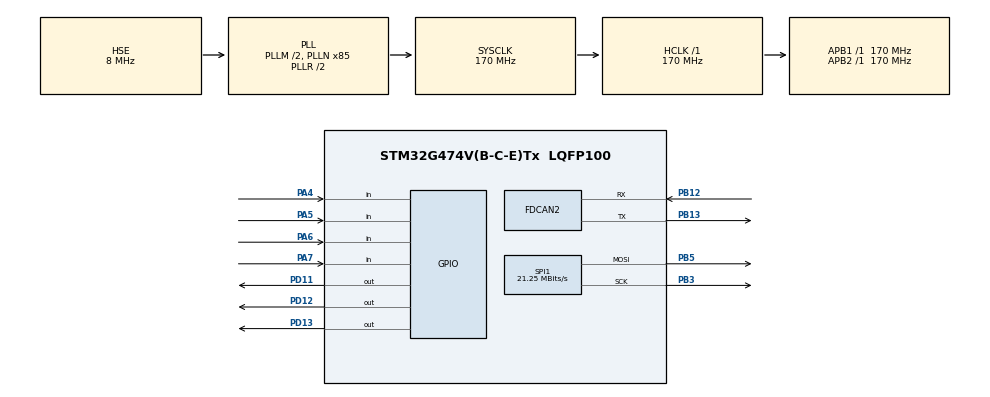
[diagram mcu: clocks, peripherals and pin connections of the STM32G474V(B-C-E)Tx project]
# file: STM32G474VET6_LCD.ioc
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Dma.Request0=SPI1_TX
Dma.SPI1_TX.0.Direction=DMA_MEMORY_TO_PERIPH
Dma.SPI1_TX.0.EventEnable=DISABLE
Dma.SPI1_TX.0.Instance=DMA1_Channel1
Dma.SPI1_TX.0.MemDataAlignment=DMA_MDATAALIGN_BYTE
Dma.SPI1_TX.0.MemInc=DMA_MINC_ENABLE
Dma.SPI1_TX.0.Mode=DMA_NORMAL
Dma.SPI1_TX.0.PeriphDataAlignment=DMA_PDATAALIGN_BYTE
Dma.SPI1_TX.0.PeriphInc=DMA_PINC_DISABLE
Dma.SPI1_TX.0.Polarity=HAL_DMAMUX_REQ_GEN_RISING
Dma.SPI1_TX.0.Priority=DMA_PRIORITY_HIGH
Dma.SPI1_TX.0.RequestNumber=1
Dma.SPI1_TX.0.SignalID=NONE
Dma.SPI1_TX.0.SyncEnable=DISABLE
Dma.SPI1_TX.0.SyncPolarity=HAL_DMAMUX_SYNC_NO_EVENT
Dma.SPI1_TX.0.SyncRequestNumber=1
Dma.SPI1_TX.0.SyncSignalID=NONE
FDCAN2.AutoRetransmission=ENABLE
FDCAN2.CalculateBaudRateNominal=499999
FDCAN2.CalculateTimeBitNominal=2000
FDCAN2.CalculateTimeQuantumNominal=117.64705882352942
FDCAN2.DataPrescaler=1
FDCAN2.DataSyncJumpWidth=1
FDCAN2.DataTimeSeg1=1
FDCAN2.DataTimeSeg2=1
FDCAN2.ExtFiltersNbr=1
FDCAN2.NominalPrescaler=20
FDCAN2.NominalSyncJumpWidth=3
FDCAN2.NominalTimeSeg1=13
FDCAN2.NominalTimeSeg2=3
FDCAN2.TransmitPause=DISABLE
Mcu.Family=STM32G4
Mcu.Name=STM32G474V(B-C-E)Tx
Mcu.Package=LQFP100
NVIC.DMA1_Channel1_IRQn=true\:0\:0\:false\:false\:true\:false\:true\:true
NVIC.PriorityGroup=NVIC_PRIORITYGROUP_4
NVIC.TIM1_BRK_TIM15_IRQn=true\:0\:0\:false\:false\:true\:true\:true\:true
NVIC.TIM1_TRG_COM_TIM17_IRQn=true\:0\:0\:false\:false\:true\:true\:true\:true
PA13.Mode=Serial_Wire
PA13.Signal=SYS_JTMS-SWDIO
PA14.Mode=Serial_Wire
PA14.Signal=SYS_JTCK-SWCLK
PA4.Signal=GPIO_Input
PA5.Signal=GPIO_Input
PA6.Signal=GPIO_Input
PA7.Signal=GPIO_Input
PB12.Mode=FDCAN_Activate
PB12.Signal=FDCAN2_RX
PB13.Mode=FDCAN_Activate
PB13.Signal=FDCAN2_TX
PB3.Mode=TX_Only_Simplex_Unidirect_Master
PB3.Signal=SPI1_SCK
PB5.Mode=TX_Only_Simplex_Unidirect_Master
PB5.Signal=SPI1_MOSI
PD11.GPIO_Speed=GPIO_SPEED_FREQ_HIGH
PD11.PinState=GPIO_PIN_SET
PD11.Signal=GPIO_Output
PD12.GPIO_Speed=GPIO_SPEED_FREQ_HIGH
PD12.PinState=GPIO_PIN_SET
PD12.Signal=GPIO_Output
PD13.GPIO_Speed=GPIO_SPEED_FREQ_HIGH
PD13.Signal=GPIO_Output
PF0-OSC_IN.Mode=HSE-External-Oscillator
PF0-OSC_IN.Signal=RCC_OSC_IN
PF1-OSC_OUT.Mode=HSE-External-Oscillator
PF1-OSC_OUT.Signal=RCC_OSC_OUT
ProjectManager.HeapSize=0x200
ProjectManager.StackSize=0x400
ProjectManager.TargetToolchain=Makefile
RCC.ADC12Freq_Value=170000000
RCC.ADC345Freq_Value=170000000
RCC.AHBFreq_Value=170000000
RCC.APB1Freq_Value=170000000
RCC.APB1TimFreq_Value=170000000
RCC.APB2Freq_Value=170000000
RCC.APB2TimFreq_Value=170000000
RCC.CortexFreq_Value=170000000
RCC.EXTERNAL_CLOCK_VALUE=12288000
RCC.HCLKFreq_Value=170000000
RCC.HSE_VALUE=8000000
RCC.HSI48_VALUE=48000000
RCC.HSI_VALUE=16000000
RCC.LSE_VALUE=32768
RCC.PLLM=RCC_PLLM_DIV2
RCC.PLLN=85
RCC.PLLSourceVirtual=RCC_PLLSOURCE_HSE
RCC.SYSCLKFreq_VALUE=170000000
RCC.SYSCLKSource=RCC_SYSCLKSOURCE_PLLCLK
RCC.USBFreq_Value=170000000
RCC.VCOOutputFreq_Value=340000000
SPI1.BaudRatePrescaler=SPI_BAUDRATEPRESCALER_8
SPI1.CalculateBaudRate=21.25 MBits/s
SPI1.DataSize=SPI_DATASIZE_8BIT
SPI1.Direction=SPI_DIRECTION_1LINE
SPI1.Mode=SPI_MODE_MASTER
SPI1.NSSPMode=SPI_NSS_PULSE_DISABLE
SPI1.VirtualType=VM_MASTER
TIM1.PeriodNoDither=10000
TIM1.Prescaler=17
TIM17.PeriodNoDither=10000
TIM17.Prescaler=170
VP_SYS_VS_DBSignals.Mode=DisableDeadBatterySignals
VP_TIM17_VS_ClockSourceINT.Mode=Enable_Timer
VP_TIM1_VS_ClockSourceINT.Mode=Internal
board=custom

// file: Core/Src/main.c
/* USER CODE BEGIN Header */
/**
  ******************************************************************************
  * @file           : main.c
  * @brief          : Main program body
  ******************************************************************************
  * @attention
  *
  * Copyright (c) 2026 STMicroelectronics.
  * All rights reserved.
  *
  * This software is licensed under terms that can be found in the LICENSE file
  * in the root directory of this software component.
  * If no LICENSE file comes with this software, it is provided AS-IS.
  *
  ******************************************************************************
  */
/* USER CODE END Header */
#include "main.h"
#include "dma.h"
#include "fdcan.h"
#include "spi.h"
#include "tim.h"
#include "gpio.h"

/* USER CODE BEGIN Includes */
#include "app_lvgl.h"
#include "lcd_hw.h"
#include "zdt_x57.h"

/* USER CODE END Includes */

void SystemClock_Config(void);

int main(void)
{

  /* MCU Configuration--------------------------------------------------------*/

  /* Reset of all peripherals, Initializes the Flash interface and the Systick. */
  HAL_Init();

  /* Configure the system clock */
  SystemClock_Config();

  /* Initialize all configured peripherals */
  MX_GPIO_Init();
  MX_DMA_Init();
  MX_SPI1_Init();
  MX_TIM1_Init();
  MX_TIM17_Init();
  MX_FDCAN2_Init();
  /* USER CODE BEGIN 2 */
  (void)ZDT_X57_BindFdcan(&hfdcan2);
  (void)LCD_HW_Init();
  App_Lvgl_Init();
  HAL_TIM_Base_Start_IT(&htim17);

  /* USER CODE END 2 */

  /* Infinite loop */
  while (1)
  {

    /* USER CODE BEGIN 3 */
    App_Lvgl_Process();
  }
  /* USER CODE END 3 */
}

void SystemClock_Config(void)
{
  RCC_OscInitTypeDef RCC_OscInitStruct = {0};
  RCC_ClkInitTypeDef RCC_ClkInitStruct = {0};

  /** Configure the main internal regulator output voltage
  */
  HAL_PWREx_ControlVoltageScaling(PWR_REGULATOR_VOLTAGE_SCALE1_BOOST);

  /** Initializes the RCC Oscillators according to the specified parameters
  * in the RCC_OscInitTypeDef structure.
  */
  RCC_OscInitStruct.OscillatorType = RCC_OSCILLATORTYPE_HSE;
  RCC_OscInitStruct.HSEState = RCC_HSE_ON;
  RCC_OscInitStruct.PLL.PLLState = RCC_PLL_ON;
  RCC_OscInitStruct.PLL.PLLSource = RCC_PLLSOURCE_HSE;
  RCC_OscInitStruct.PLL.PLLM = RCC_PLLM_DIV2;
  RCC_OscInitStruct.PLL.PLLN = 85;
  RCC_OscInitStruct.PLL.PLLP = RCC_PLLP_DIV2;
  RCC_OscInitStruct.PLL.PLLQ = RCC_PLLQ_DIV2;
  RCC_OscInitStruct.PLL.PLLR = RCC_PLLR_DIV2;
  if (HAL_RCC_OscConfig(&RCC_OscInitStruct) != HAL_OK)
  {
    Error_Handler();
  }

  /** Initializes the CPU, AHB and APB buses clocks
  */
  RCC_ClkInitStruct.ClockType = RCC_CLOCKTYPE_HCLK|RCC_CLOCKTYPE_SYSCLK
                              |RCC_CLOCKTYPE_PCLK1|RCC_CLOCKTYPE_PCLK2;
  RCC_ClkInitStruct.SYSCLKSource = RCC_SYSCLKSOURCE_PLLCLK;
  RCC_ClkInitStruct.AHBCLKDivider = RCC_SYSCLK_DIV1;
  RCC_ClkInitStruct.APB1CLKDivider = RCC_HCLK_DIV1;
  RCC_ClkInitStruct.APB2CLKDivider = RCC_HCLK_DIV1;

  if (HAL_RCC_ClockConfig(&RCC_ClkInitStruct, FLASH_LATENCY_4) != HAL_OK)
  {
    Error_Handler();
  }
}

void Error_Handler(void)
{
  __disable_irq();
  while (1)
  {
  }
}
